VERSION ""

NS_ :

BS_:

BU_: ECUA ECUB

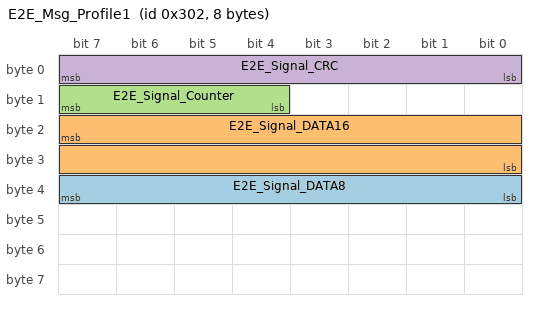
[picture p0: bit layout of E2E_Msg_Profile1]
BO_ 770 E2E_Msg_Profile1: 8 ECUA
 SG_ E2E_Signal_DATA8 : 32|8@1- (1,0) [0|0] "" Vector__XXX
 SG_ E2E_Signal_DATA16 : 23|16@0+ (1,0) [0|0] ""  ECUB
 SG_ E2E_Signal_Counter : 15|4@0+ (1,0) [0|0] ""  ECUB
 SG_ E2E_Signal_CRC : 7|8@0+ (1,0) [0|0] ""  ECUB

BA_DEF_ SG_  "GenSigSendType" ENUM  "Cyclic","OnWrite","OnWriteWithRepetition","OnChange","OnChangeWithRepetition","IfActive","IfActiveWithRepetition","NoSigSendType";
BA_DEF_ BO_  "GenMsgCycleTime" INT 0 0;
BA_DEF_ BO_  "GenMsgSendType" ENUM  "Cyclic","not_used","not_used","not_used","not_used","Cyclic","not_used","IfActive","NoMsgSendType";
BA_DEF_ BU_  "NmStationAddress" HEX 0 0;
BA_DEF_  "DBName" STRING ;
BA_DEF_  "BusType" STRING ;
BA_DEF_DEF_  "GenSigSendType" "Cyclic";
BA_DEF_DEF_  "GenMsgCycleTime" 0;
BA_DEF_DEF_  "GenMsgSendType" "NoMsgSendType";
BA_DEF_DEF_  "NmStationAddress" 0;
BA_DEF_DEF_  "DBName" "";
BA_DEF_DEF_  "BusType" "CAN";
BA_ "DBName" "ECUAB";
BA_ "NmStationAddress" BU_ ECUA 1;
BA_ "GenMsgCycleTime" BO_ 770 100;
BA_ "GenMsgSendType" BO_ 770 0;
SIG_GROUP_ 770 E2E_Demo_Group1 1 : E2E_Signal_DATA8 E2E_Signal_Counter E2E_Signal_CRC E2E_Signal_DATA16;
